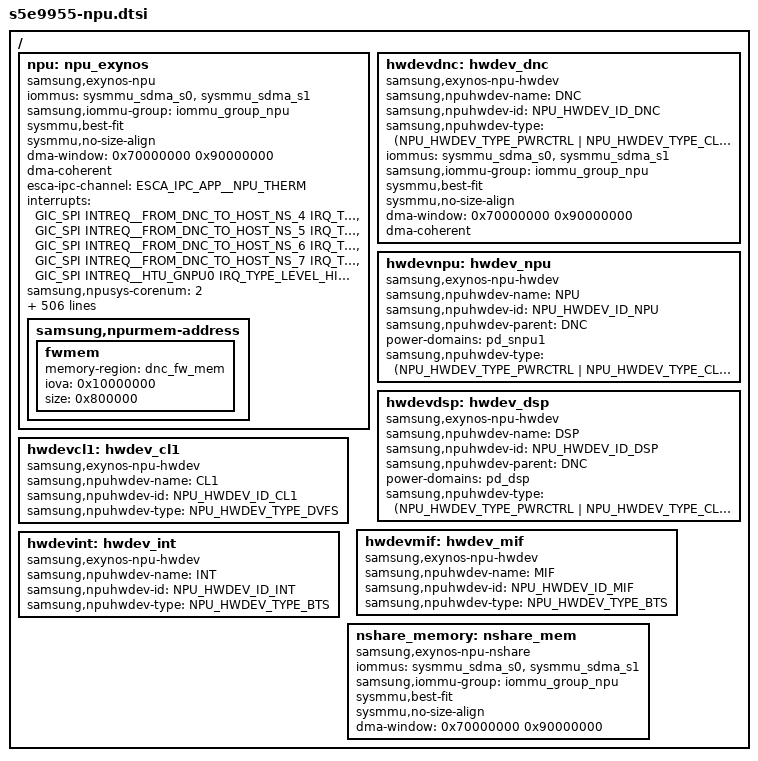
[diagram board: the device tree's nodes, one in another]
/*
 * SAMSUNG EXYNOS9955 NPU device tree source
 *
 * Copyright (c) 2024 Samsung Electronics Co., Ltd.
 *		http://www.samsung.com
 *
 * SAMSUNG EXYNOS9955 NPU device nodes are listed in this file.
 * EXYNOS based board files can include this file and provide
 * values for board specfic bindings.
 *
 * This program is free software; you can redistribute it and/or modify
 * it under the terms of the GNU General Public License version 2 as
 * published by the Free Software Foundation.
 */
#include <dt-bindings/clock/s5e9955.h>
#include <dt-bindings/soc/samsung/s5e9955-npu.h>
#include <dt-bindings/soc/samsung/s5e9955-esca-ipc.h>

/ {
	npu: npu_exynos {
		compatible = "samsung,exynos-npu";
		iommus = <&sysmmu_sdma_s0>, <&sysmmu_sdma_s1>;
		samsung,iommu-group = <&iommu_group_npu>;
		sysmmu,best-fit;
		sysmmu,no-size-align;
		#dma-address-cells = <1>;
		#dma-size-cells = <1>;
		dma-window = <0x70000000 0x90000000>;
		dma-coherent;
		esca-ipc-channel = <ESCA_IPC_APP__NPU_THERM>;

		interrupts =
			<GIC_SPI INTREQ__FROM_DNC_TO_HOST_NS_4 IRQ_TYPE_LEVEL_HIGH>,
			<GIC_SPI INTREQ__FROM_DNC_TO_HOST_NS_5 IRQ_TYPE_LEVEL_HIGH>,
			<GIC_SPI INTREQ__FROM_DNC_TO_HOST_NS_6 IRQ_TYPE_LEVEL_HIGH>,
			<GIC_SPI INTREQ__FROM_DNC_TO_HOST_NS_7 IRQ_TYPE_LEVEL_HIGH>,
			<GIC_SPI INTREQ__HTU_GNPU0 IRQ_TYPE_LEVEL_HIGH>;

		samsung,npusys-corenum = <2>;
		/* refer to npu-system.h for memory names
		 * you can add init settings for each memory area
		 */
		samsung,npumem-address = /* 0 start      size */
			<0 0x20000000 0x100000>,
			<0 0x20100000 0x100000>,
			<0 0x20200000 0x100000>,
			<0 0x20300000 0x100000>,
			<0 0x20400000 0x100000>,
			<0 0x20500000 0x100000>,
			<0 0x20600000 0x100000>,

			<0 0x21200000 0x900000>,
			<0 0x21200000 0x100000>,
			<0 0x21300000 0x200000>,
			<0 0x21500000 0x100000>,
			<0 0x21600000 0x100000>,
			<0 0x21700000 0x100000>,
			<0 0x21800000 0x100000>,
			<0 0x21900000 0x100000>,
			<0 0x21A00000 0x100000>,
			<0 0x220c0000 0x10000>,

			<0 0x400D000 0x1000>,
			<0 0x9406000 0x1000>,
			<0 0x9403000 0x1000>,
			<0 0x9404000 0x1000>,
			<0 0x13890000 0x10000>,

			<0 0x2DCA0000 0x60000>,

			<0 0x20020000 0x1000>,
			<0 0x2002084C 0x100>,
			<0 0x20022000 0x4000>,
			<0 0x20020838 0x100>,
			<0 0x216D0000 0x1000>,
			<0 0x217D0000 0x1000>,
			<0 0x218D0000 0x1000>,
			<0 0x219D0000 0x1000>,
			<0 0x13CD0000 0x10000>,

			<0 0x11100000 0x200000>,
			<2 0x11300000 0x1800000>,
			<0 0x13300000 0x800000>,
			<0 0x14000000 0x1000000>,
			<0 0x10D00000 0x100000>,
			<0 0x10E00000 0x200000>,
			<0 0x11000000 0x1000>,
			<0 0x11001000 0x7000>,
			<0 0x11008000 0xF8000>,
			<0 0x30000000 0x40000000>,
			<0 0x0 0x3000>;
		samsung,npumem-names =
				"sfrdnc",	"SFR",
				"sfrsdma",	"SFR",
				"sfrgnpu0",	"SFR",
				"sfrgnpu1",	"SFR",
				"sfrdsp0",	"SFR",
				"sfrsnpu0",	"SFR",
				"sfrsnpu1",	"SFR",

				"sfrblkall",	"SFR",
				"sfrblkdnc",	"SFR",
				"sfrblksdma",	"SFR",
				"sfrblkdsp0",	"SFR",
				"sfrblkgnpu0",	"SFR",
				"sfrblkgnpu1",	"SFR",
				"sfrblksnpu0",	"SFR",
				"sfrblksnpu1",	"SFR",
				"sfrblknpumem",	"SFR",
				"gpuc2a",	"SFR",

				"sfrcoresight",	"SFR",
				"sfrcssys_npu",	"SFR",
				"sfrstm",	"SFR",
				"sfrstm1",	"SFR",
				"sfrmctg",	"SFR",

				"pmu_sub",	"SFR",

				"sfrmboxmmap",	"SFR",
				"sfrmbox0",	"SFR",
				"sfrmbox1",	"SFR",
				"sfrmbox2",	"SFR",
				"htugnpu0",	"SFR",
				"htugnpu1",	"SFR",
				"htusnpu0",	"SFR",
				"htusnpu1",	"SFR",
				"mboxapm1dnc",	"SFR",

				"fwmbox",	"fwmbox",
				"llc",		"llc",
				"fwunittest",	"fwunittest",
				"ivp_pm",	"dsp_ivp_pm.bin",
				"dl_out",	"dl_out",
				"dsp_mem",	"dsp_mem",
				"dhcp",		"dhcp",
				"ivp_dm",	"dsp_ivp_dm.bin",
				"fwlog",	"fwlog",
				"CHUNK_IMB",	"IMB",
				"CMDQ_TABLE",	"";

		/* examples of memory area init
		 *	offset,	val,	mask,
		 * samsung,npumem-baaw =
		 *	<0x00, 0x017B00, 0xFFFFFF>,
		 *	<0x00, 0x017B40, 0xFFFFFF>,
		 *	...;
		 */

		/* examples of reg cmd
		 *	sfr : name of memory area
		 *	data :
		 *	<rw	offset	val	mask	mdelay>,
		 */

		samsung,npucmd-npupgon-sfr =
			"sfrblksdma",
			"sfrblknpumem",
			"sfrblkgnpu0",
			"sfrblkgnpu1",
			"sfrblksnpu0",
			"sfrblksnpu1";
		samsung,npucmd-npupgon-data =
			<1	0x30000	0x1	0x00000001	0>,
			<1	0x40000	0x1	0x00000001	0>,
			<1	0x40000	0x1	0x00000001	0>,
			<1	0x40000	0x1	0x00000001	0>,
			<1	0x40000	0x1	0x00000001	0>,
			<1	0x40000	0x1	0x00000001	0>;

		samsung,npucmd-dsppgon-sfr =
			"sfrblksdma",
			"sfrblkdsp0";
		samsung,npucmd-dsppgon-data =
			<1	0x30000	0x1	0x00000001	0>,
			<1	0x30000	0x1	0x00000001	0>;

		samsung,npucmd-npupgoff-sfr =
			"sfrblksdma",
			"sfrblknpumem",
			"sfrblkgnpu0",
			"sfrblkgnpu1",
			"sfrblksnpu0",
			"sfrblksnpu1";
		samsung,npucmd-npupgoff-data =
			<1	0x30000	0x0	0x00000001	0>,
			<1	0x40000	0x0	0x00000001	0>,
			<1	0x40000	0x0	0x00000001	0>,
			<1	0x40000	0x0	0x00000001	0>,
			<1	0x40000	0x0	0x00000001	0>,
			<1	0x40000	0x0	0x00000001	0>;

		samsung,npucmd-dsppgoff-sfr =
			"sfrblksdma",
			"sfrblkdsp0";
		samsung,npucmd-dsppgoff-data =
			<1	0x30000	0x0	0x00000001	0>,
			<1	0x30000	0x0	0x00000001	0>;

		samsung,npucmd-cpuon-sfr =
			/* DNC boot up */
			"sfrdnc",
			"sfrdnc",
			"sfrdnc",
			"sfrdnc",
			"sfrdnc",
			"sfrdnc",
			"sfrdnc";
		/*	cmd	offset	value	mask		delay */
		samsung,npucmd-cpuon-data =
		/* to power on, DNC_CPU_ALIVE_CTRL.CPU_ALIVE_CTRL should be 0 */
			<3	0xE0054	0x00000000	0xFFFFFFFF	0>,
			<1	0xE011C	0x00000000	0xFFFFFFFF	0>,
			<1	0xE0000	0x00000001	0xFFFFFFFF	0>,
			<3	0xE0004	0x00000001	0xFFFFFFFF	0>,
			<1	0xE0008	0x10000000	0xFFFFFFFF	0>,
			<3	0xE000C	0x10000000	0xFFFFFFFF	0>,
			<3	0xE0040	0x00000003	0xFFFFFFFF	0>;

		samsung,npucmd-cpuon64-sfr =
			/* DNC boot up */
			"sfrblkdnc",
			"sfrdnc",
			"sfrdnc",
			"sfrdnc",
			"sfrdnc",
			"sfrdnc",
			"sfrdnc",
			"sfrdnc";
		/*	cmd	offset	value	mask		delay */
		samsung,npucmd-cpuon64-data =
		/* to power on, DNC_CPU_ALIVE_CTRL.CPU_ALIVE_CTRL should be 0 */
			<1	0x600	0x00000010	0x00000010	0>,
			<3	0xE0054	0x00000001	0xFFFFFFFF	0>,
			<1	0xE011C	0x00000000	0xFFFFFFFF	0>,
			<1	0xE0000	0x00000001	0xFFFFFFFF	0>,
			<3	0xE0004	0x00000001	0xFFFFFFFF	0>,
			<1	0xE0008	0x10000000	0xFFFFFFFF	0>,
			<3	0xE000C	0x10000000	0xFFFFFFFF	0>,
			<3	0xE0040	0x00000003	0xFFFFFFFF	0>;

		samsung,npucmd-llcaid-sfr =
			"sfrblksdma",
			"sfrblksdma",
			"sfrblksdma",
			"sfrblksdma",
			"sfrblksdma",
			"sfrblksdma",
			"sfrblksdma",
			"sfrblksdma",
			"sfrblksdma",
			"sfrblksdma",
			"sfrblksdma",
			"sfrblksdma",
			"sfrblksdma",
			"sfrblksdma",
			"sfrblksdma",
			"sfrblksdma",
			"sfrblksdma",
			"sfrblksdma",
			"sfrblksdma",
			"sfrblksdma";
		/*	cmd	offset	value	mask		delay */
		samsung,npucmd-llcaid-data =
		/* llcaid stream */
			<1	0xD0420	0x101 0xFFFFFFFF 0>,
			<1	0xD0424	0xC000003 0xFFFFFFFF 0>,
			<1	0xD0428	0xC000003 0xFFFFFFFF 0>,
			<1	0xE0420	0x101 0xFFFFFFFF 0>,
			<1	0xE0424	0xC000003 0xFFFFFFFF 0>,
			<1	0xE0428	0xC000003 0xFFFFFFFF 0>,
			<1	0xF0420	0x101 0xFFFFFFFF 0>,
			<1	0xF0424	0xC000003 0xFFFFFFFF 0>,
			<1	0xF0428	0xC000003 0xFFFFFFFF 0>,
			<1	0x100420 0x101 0xFFFFFFFF 0>,
			<1	0x100424 0xC000003 0xFFFFFFFF 0>,
			<1	0x100428 0xC000003 0xFFFFFFFF 0>,
		/* llcaid master */
			<1	0xD0404	0xC000000 0xFFFFFFFF 0>,
			<1	0xD0408	0xC000000 0xFFFFFFFF 0>,
			<1	0xE0404	0xC000000 0xFFFFFFFF 0>,
			<1	0xE0408	0xC000000 0xFFFFFFFF 0>,
			<1	0xF0404	0xC000000 0xFFFFFFFF 0>,
			<1	0xF0408	0xC000000 0xFFFFFFFF 0>,
			<1	0x100404 0xC000000 0xFFFFFFFF 0>,
			<1	0x100408 0xC000000 0xFFFFFFFF 0>;

		samsung,npucmd-cpuoff-sfr =
			"sfrblkdnc",
			"sfrdnc";
		samsung,npucmd-cpuoff-data =
		/* to power off NPU cores, HWACG should be enable */
			<1	0x600	0x00		0x00000010	0>,
			<3	0xE0040	0x00000000	0xFFFFFFFF	0>;

		samsung,npucmd-cpupc-sfr =
			"sfrdnc",
			"sfrdnc";
		samsung,npucmd-cpupc-data =
			<0	0xE00CC	0x00	0xFFFFFFFF	0>,
			<0	0xE00D0	0x00	0xFFFFFFFF	0>;

		samsung,npucmd-gnpucmdqpc-sfr =
			"sfrgnpu0",
			"sfrgnpu0",
			"sfrgnpu1",
			"sfrgnpu1";
		samsung,npucmd-gnpucmdqpc-data =
			<0	0x2300	0x00	0xFFFFFFFF	0>,
			<0	0x4300	0x00	0xFFFFFFFF	0>,
			<0	0x2300	0x00	0xFFFFFFFF	0>,
			<0	0x4300	0x00	0xFFFFFFFF	0>;

		samsung,npucmd-dspcmdqpc-sfr =
			"sfrdsp0",
			"sfrdsp0";
		samsung,npucmd-dspcmdqpc-data =
			<0	0x12300	0x00	0xFFFFFFFF	0>,
			<0	0x14300	0x00	0xFFFFFFFF	0>;

		samsung,npucmd-afmgnpu0en-sfr =
			"htugnpu0",
			"htugnpu0",
			"htugnpu0",
			"htugnpu0",
			"htugnpu0",
			"htugnpu0",
			"htugnpu0",
			"htugnpu0";
		samsung,npucmd-afmgnpu0en-data =
			<1	0x200	0x00000020	0x00000020	0>,
			<1	0x06C	0x08A00008	0x08E000FC	0>,
			<1	0x080	0x02000001	0xFFF0FFF3	0>,
			<1	0x020	0x00003000	0x00003800	0>,
			<1	0x048	0x3FF0003F	0x3FF000FF	0>,
			<1	0x200	0x80000000	0x80000000	0>,
			<1	0x118	0x80000000	0xFFFFFFFF	0>,
			<1	0x000	0x00000001	0x00000001	0>;

		samsung,npucmd-afmgnpu0dis-sfr =
			"htugnpu0",
			"htugnpu0",
			"htugnpu0",
			"htugnpu0",
			"htugnpu0",
			"htugnpu0",
			"htugnpu0",
			"htugnpu0";
		samsung,npucmd-afmgnpu0dis-data =
			<1	0x200	0x00	0x00000020	0>,
			<1	0x06C	0x00	0x08E000FC	0>,
			<1	0x080	0x00	0xFFF0FFF3	0>,
			<1	0x020	0x00	0x00003800	0>,
			<1	0x048	0x00	0x3FF000FF	0>,
			<1	0x200	0x00	0x80000000	0>,
			<1	0x118	0x00	0xFFFFFFFF	0>,
			<1	0x000	0x00	0x00000001	0>;

		samsung,npucmd-afmgnpu1en-sfr =
			"htugnpu1",
			"htugnpu1",
			"htugnpu1",
			"htugnpu1",
			"htugnpu1",
			"htugnpu1",
			"htugnpu1",
			"htugnpu1";
		samsung,npucmd-afmgnpu1en-data =
			<1	0x200	0x00000020	0x00000020	0>,
			<1	0x06C	0x08A00008	0x08E000FC	0>,
			<1	0x080	0x02000001	0xFFF0FFF3	0>,
			<1	0x020	0x00003000	0x00003800	0>,
			<1	0x048	0x3FF0003F	0x3FF000FF	0>,
			<1	0x200	0x80000000	0x80000000	0>,
			<1	0x118	0x80000000	0xFFFFFFFF	0>,
			<1	0x000	0x00000001	0x00000001	0>;

		samsung,npucmd-afmgnpu1dis-sfr =
			"htugnpu1",
			"htugnpu1",
			"htugnpu1",
			"htugnpu1",
			"htugnpu1",
			"htugnpu1",
			"htugnpu1",
			"htugnpu1";
		samsung,npucmd-afmgnpu1dis-data =
			<1	0x200	0x00	0x00000020	0>,
			<1	0x06C	0x00	0x08E000FC	0>,
			<1	0x080	0x00	0xFFF0FFF3	0>,
			<1	0x020	0x00	0x00003800	0>,
			<1	0x048	0x00	0x3FF000FF	0>,
			<1	0x200	0x00	0x80000000	0>,
			<1	0x118	0x00	0xFFFFFFFF	0>,
			<1	0x000	0x00	0x00000001	0>;

		samsung,npucmd-afmsnpu0en-sfr =
			"htusnpu0",
			"htusnpu0",
			"htusnpu0",
			"htusnpu0",
			"htusnpu0",
			"htusnpu0",
			"htusnpu0",
			"htusnpu0";
		samsung,npucmd-afmsnpu0en-data =
			<1	0x200	0x00000020	0x00000020	0>,
			<1	0x06C	0x08A00008	0x08E000FC	0>,
			<1	0x080	0x02000001	0xFFF0FFF3	0>,
			<1	0x020	0x00003000	0x00003800	0>,
			<1	0x048	0x3FF0003F	0x3FF000FF	0>,
			<1	0x200	0x80000000	0x80000000	0>,
			<1	0x118	0x80000000	0xFFFFFFFF	0>,
			<1	0x000	0x00000001	0x00000001	0>;

		samsung,npucmd-afmsnpu0dis-sfr =
			"htusnpu0",
			"htusnpu0",
			"htusnpu0",
			"htusnpu0",
			"htusnpu0",
			"htusnpu0",
			"htusnpu0",
			"htusnpu0";
		samsung,npucmd-afmsnpu0dis-data =
			<1	0x200	0x00	0x00000020	0>,
			<1	0x06C	0x00	0x08E000FC	0>,
			<1	0x080	0x00	0xFFF0FFF3	0>,
			<1	0x020	0x00	0x00003800	0>,
			<1	0x048	0x00	0x3FF000FF	0>,
			<1	0x200	0x00	0x80000000	0>,
			<1	0x118	0x00	0xFFFFFFFF	0>,
			<1	0x000	0x00	0x00000001	0>;

		samsung,npucmd-afmsnpu1en-sfr =
			"htusnpu1",
			"htusnpu1",
			"htusnpu1",
			"htusnpu1",
			"htusnpu1",
			"htusnpu1",
			"htusnpu1",
			"htusnpu1";
		samsung,npucmd-afmsnpu1en-data =
			<1	0x200	0x00000020	0x00000020	0>,
			<1	0x06C	0x08A00008	0x08E000FC	0>,
			<1	0x080	0x02000001	0xFFF0FFF3	0>,
			<1	0x020	0x00003000	0x00003800	0>,
			<1	0x048	0x3FF0003F	0x3FF000FF	0>,
			<1	0x200	0x80000000	0x80000000	0>,
			<1	0x118	0x80000000	0xFFFFFFFF	0>,
			<1	0x000	0x00000001	0x00000001	0>;

		samsung,npucmd-afmsnpu1dis-sfr =
			"htusnpu1",
			"htusnpu1",
			"htusnpu1",
			"htusnpu1",
			"htusnpu1",
			"htusnpu1",
			"htusnpu1",
			"htusnpu1";
		samsung,npucmd-afmsnpu1dis-data =
			<1	0x200	0x00	0x00000020	0>,
			<1	0x06C	0x00	0x08E000FC	0>,
			<1	0x080	0x00	0xFFF0FFF3	0>,
			<1	0x020	0x00	0x00003800	0>,
			<1	0x048	0x00	0x3FF000FF	0>,
			<1	0x200	0x00	0x80000000	0>,
			<1	0x118	0x00	0xFFFFFFFF	0>,
			<1	0x000	0x00	0x00000001	0>;

		samsung,npucmd-chkgnpu0itr-sfr =
			"htugnpu0";
		samsung,npucmd-chkgnpu0itr-data =
			<0	0x06C	0x08000000	0x08000000	0>;

		samsung,npucmd-clrgnpu0itr-sfr =
			"htugnpu0";
		samsung,npucmd-clrgnpu0itr-data =
			<1	0x06C	0x08000000	0x08000000	0>;

		samsung,npucmd-engnpu0itr-sfr =
			"htugnpu0";
		samsung,npucmd-engnpu0itr-data =
			<1	0x080	0x00000003	0x00000003	0>;

		samsung,npucmd-disgnpu0itr-sfr =
			"htugnpu0";
		samsung,npucmd-disgnpu0itr-data =
			<1	0x080	0x00	0x00000003	0>;

		samsung,npucmd-clrgnpu0tdc-sfr =
			"htugnpu0";
		samsung,npucmd-clrgnpu0tdc-data =
			<1	0x080	0x00	0x0000FFF0	0>;

		samsung,npucmd-chkgnpu0tdc-sfr =
			"htugnpu0";
		samsung,npucmd-chkgnpu0tdc-data =
			<0	0x080	0x00	0x0000FFF0	0>;

		samsung,npucmd-clrdncdiv-sfr =
			"sfrblkdnc",
			"sfrblksdma";
		samsung,npucmd-clrdncdiv-data =
			<1	0x830	0x00	0x00000010	0>,
			<1	0x830	0x00	0x00000010	0>;

		samsung,npucmd-clrgnpu0div-sfr =
			"sfrblkgnpu0";
		samsung,npucmd-clrgnpu0div-data =
			<1	0x830	0x00	0x00000010	0>;

		samsung,npucmd-clrgnpu1div-sfr =
			"sfrblkgnpu1";
		samsung,npucmd-clrgnpu1div-data =
			<1	0x830	0x00	0x00000010	0>;

		samsung,npucmd-clrdspdiv-sfr =
			"sfrblkdsp0";
		samsung,npucmd-clrdspdiv-data =
			<1	0x830	0x00	0x00000010	0>;

		samsung,npucmd-enablestm-sfr =
			"sfrdnc",
			"sfrsdma",
			"sfrgnpu0",
			"sfrgnpu1",
			"sfrsnpu0",
			"sfrsnpu0",
			"sfrsnpu0",
			"sfrsnpu1",
			"sfrsnpu1",
			"sfrsnpu1",
			"sfrdsp0";
		/*	cmd	offset	value	mask		delay */
		samsung,npucmd-enablestm-data =
			<1	0x20014	0x1	0x00000001	0>,
			<1	0xF800	0x80000000	0x80000000	0>,
			<1	0x10004	0x1	0x00000001	0>,
			<1	0x10004	0x1	0x00000001	0>,
			<1	0x10004	0x1	0x00000001	0>,
			<1	0xB0200	0x1	0x00000001	0>,
			<1	0xF0200	0x1	0x00000001	0>,
			<1	0x10004	0x1	0x00000001	0>,
			<1	0xB0200	0x1	0x00000001	0>,
			<1	0xF0200	0x1	0x00000001	0>,
			<1	0x01E8	0x1	0x00000001	0>;

		samsung,npucmd-disablestm-sfr =
			"sfrdsp0",
			"sfrsnpu0",
			"sfrsnpu0",
			"sfrsnpu0",
			"sfrsnpu1",
			"sfrsnpu1",
			"sfrsnpu1",
			"sfrgnpu0",
			"sfrgnpu1",
			"sfrsdma",
			"sfrdnc";
		/*	cmd	offset	value	mask		delay */
		samsung,npucmd-disablestm-data =
			<1	0x01E8	0x0	0x00000001	0>,
			<1	0x10004	0x0	0x00000001	0>,
			<1	0xB0200	0x0	0x00000001	0>,
			<1	0xF0200	0x0	0x00000001	0>,
			<1	0x10004	0x0	0x00000001	0>,
			<1	0xB0200	0x0	0x00000001	0>,
			<1	0xF0200	0x0	0x00000001	0>,
			<1	0x10004	0x0	0x00000001	0>,
			<1	0x10004	0x0	0x00000001	0>,
			<1	0xF800	0x0	0x80000000	0>,
			<1	0x20014	0x0	0x00000001	0>;

		samsung,npucmd-enstmdnc-sfr =
		/* DNC enable stm */
			"sfrdnc",
			"sfrsdma";
		/*	cmd	offset	value	mask		delay */
		samsung,npucmd-enstmdnc-data =
		/* DNC enable stm */
			<1	0x20014	0x1	0x00000001	0>,
			<1	0xF800	0x80000000	0x80000000	0>;

		samsung,npucmd-disstmdnc-sfr =
		/* DNC disable stm */
			"sfrsdma",
			"sfrdnc";
		/*	cmd	offset	value	mask		delay */
		samsung,npucmd-disstmdnc-data =
		/* DNC disable stm */
			<1	0xF800	0x0	0x80000000	0>,
			<1	0x20014	0x0	0x00000001	0>;

		samsung,npucmd-enstmdsp-sfr =
		/* DSP enable stm */
			"sfrdsp0";
		/*	cmd	offset	value	mask		delay */
		samsung,npucmd-enstmdsp-data =
		/* DSP enable stm */
			<1	0x01E8	0x1	0x00000001	0>;

		samsung,npucmd-disstmdsp-sfr =
		/* DSP disable stm */
			"sfrdsp0";
		/*	cmd	offset	value	mask		delay */
		samsung,npucmd-disstmdsp-data =
		/* DSP disable stm */
			<1	0x01E8	0x0	0x00000001	0>;

		samsung,npucmd-enstmnpu-sfr =
		/* NPU enable stm */
			"sfrsnpu0",
			"sfrsnpu0",
			"sfrsnpu0",
			"sfrsnpu1",
			"sfrsnpu1",
			"sfrsnpu1",
			"sfrgnpu0",
			"sfrgnpu1";
		/*	cmd	offset	value	mask		delay */
		samsung,npucmd-enstmnpu-data =
		/* NPU enable stm */
			<1	0x10004	0x1	0x00000001	0>,
			<1	0xB0200	0x1	0x00000001	0>,
			<1	0xF0200	0x1	0x00000001	0>,
			<1	0x10004	0x1	0x00000001	0>,
			<1	0xB0200	0x1	0x00000001	0>,
			<1	0xF0200	0x1	0x00000001	0>,
			<1	0x10004	0x1	0x00000001	0>,
			<1	0x10004	0x1	0x00000001	0>;

		samsung,npucmd-disstmnpu-sfr =
		/* NPU disble stm */
			"sfrsnpu0",
			"sfrsnpu0",
			"sfrsnpu0",
			"sfrsnpu1",
			"sfrsnpu1",
			"sfrsnpu1",
			"sfrgnpu0",
			"sfrgnpu1";
		/*	cmd	offset	value	mask		delay */
		samsung,npucmd-disstmnpu-data =
		/* NPU disble stm */
			<1	0x10004	0x0	0x00000001	0>,
			<1	0xB0200	0x0	0x00000001	0>,
			<1	0xF0200	0x0	0x00000001	0>,
			<1	0x10004	0x0	0x00000001	0>,
			<1	0xB0200	0x0	0x00000001	0>,
			<1	0xF0200	0x0	0x00000001	0>,
			<1	0x10004	0x0	0x00000001	0>,
			<1	0x10004	0x0	0x00000001	0>;

		samsung,npucmd-allow64stm-sfr =
			"sfrstm",
			"sfrstm",
			"sfrstm",
			"sfrstm",
			"sfrstm",
			"sfrstm",
			"sfrstm";
		/*	cmd	offset	value	mask		delay */
		samsung,npucmd-allow64stm-data =
			<3	0x0D64	0x0		0xFFFFFFFF	0>,
			<3	0x0D60	0x0		0x00000001	0>,
			<3	0x0D20	0xFFFFFFFF	0xFFFFFFFF	0>,
			<3	0x0D00	0xFFFFFFFF	0xFFFFFFFF	0>,
			<3	0x0D60	0x1		0x00000001	0>,
			<3	0x0D20	0xFFFFFFFF	0xFFFFFFFF	0>,
			<3	0x0D00	0xFFFFFFFF	0xFFFFFFFF	0>;

		samsung,npucmd-allow64stm1-sfr =
			"sfrstm1",
			"sfrstm1",
			"sfrstm1",
			"sfrstm1",
			"sfrstm1",
			"sfrstm1",
			"sfrstm1";
		samsung,npucmd-allow64stm1-data =
			<3	0x0D64	0x0		0xFFFFFFFF	0>,
			<3	0x0D60	0x0		0x00000001	0>,
			<3	0x0D20	0xFFFFFFFF	0xFFFFFFFF	0>,
			<3	0x0D00	0xFFFFFFFF	0xFFFFFFFF	0>,
			<3	0x0D60	0x1		0x00000001	0>,
			<3	0x0D20	0xFFFFFFFF	0xFFFFFFFF	0>,
			<3	0x0D00	0xFFFFFFFF	0xFFFFFFFF	0>;

		samsung,npucmd-allow64ns-sfr =
			"sfrstm",
			"sfrstm",
			"sfrstm",
			"sfrstm",
			"sfrstm",
			"sfrstm",
			"sfrstm";
		/*	cmd	offset	value	mask		delay */
		samsung,npucmd-allow64ns-data =
			<1	0x0D64	0x0		0xFFFFFFFF	0>,
			<1	0x0D60	0x0		0x00000001	0>,
			<1	0x0D20	0xFFFFFFFF	0xFFFFFFFF	0>,
			<1	0x0D00	0xFFFFFFFF	0xFFFFFFFF	0>,
			<1	0x0D60	0x1		0x00000001	0>,
			<1	0x0D20	0xFFFFFFFF	0xFFFFFFFF	0>,
			<1	0x0D00	0xFFFFFFFF	0xFFFFFFFF	0>;

		samsung,npucmd-allow64ns1-sfr =
			"sfrstm1",
			"sfrstm1",
			"sfrstm1",
			"sfrstm1",
			"sfrstm1",
			"sfrstm1",
			"sfrstm1";
		samsung,npucmd-allow64ns1-data =
			<1	0x0D64	0x0		0xFFFFFFFF	0>,
			<1	0x0D60	0x0		0x00000001	0>,
			<1	0x0D20	0xFFFFFFFF	0xFFFFFFFF	0>,
			<1	0x0D00	0xFFFFFFFF	0xFFFFFFFF	0>,
			<1	0x0D60	0x1		0x00000001	0>,
			<1	0x0D20	0xFFFFFFFF	0xFFFFFFFF	0>,
			<1	0x0D00	0xFFFFFFFF	0xFFFFFFFF	0>;


		samsung,npucmd-sdma_vc0-sfr =
			"sfrsdma",
			"sfrsdma",
			"sfrsdma",
			"sfrsdma",
			"sfrsdma",
			"sfrsdma",
			"sfrsdma",
			"sfrsdma",
			"sfrsdma",
			"sfrsdma",
			"sfrsdma",
			"sfrsdma",
			"sfrsdma",
			"sfrsdma",
			"sfrsdma",
			"sfrsdma";
		samsung,npucmd-sdma_vc0-data =
			<1	0xF900	0x00	0x0000001F	0>,
			<1	0xF904	0x01	0x0000001F	0>,
			<1	0xF908	0x02	0x0000001F	0>,
			<1	0xF90C	0x03	0x0000001F	0>,
			<1	0xF910	0x04	0x0000001F	0>,
			<1	0xF914	0x05	0x0000001F	0>,
			<1	0xF918	0x06	0x0000001F	0>,
			<1	0xF91C	0x07	0x0000001F	0>,
			<1	0xF920	0x08	0x0000001F	0>,
			<1	0xF924	0x09	0x0000001F	0>,
			<1	0xF928	0x0A	0x0000001F	0>,
			<1	0xF92C	0x0B	0x0000001F	0>,
			<1	0xF930	0x0C	0x0000001F	0>,
			<1	0xF934	0x0D	0x0000001F	0>,
			<1	0xF938	0x0E	0x0000001F	0>,
			<1	0xF93C	0x0F	0x0000001F	0>;

		samsung,npucmd-sdma_vc1-sfr =
			"sfrsdma",
			"sfrsdma",
			"sfrsdma",
			"sfrsdma",
			"sfrsdma",
			"sfrsdma",
			"sfrsdma",
			"sfrsdma",
			"sfrsdma",
			"sfrsdma",
			"sfrsdma",
			"sfrsdma",
			"sfrsdma",
			"sfrsdma",
			"sfrsdma",
			"sfrsdma";
		samsung,npucmd-sdma_vc1-data =
			<1	0xF900	0x10	0x0000001F	0>,
			<1	0xF904	0x11	0x0000001F	0>,
			<1	0xF908	0x12	0x0000001F	0>,
			<1	0xF90C	0x13	0x0000001F	0>,
			<1	0xF910	0x14	0x0000001F	0>,
			<1	0xF914	0x15	0x0000001F	0>,
			<1	0xF918	0x16	0x0000001F	0>,
			<1	0xF91C	0x17	0x0000001F	0>,
			<1	0xF920	0x18	0x0000001F	0>,
			<1	0xF924	0x19	0x0000001F	0>,
			<1	0xF928	0x1A	0x0000001F	0>,
			<1	0xF92C	0x1B	0x0000001F	0>,
			<1	0xF930	0x1C	0x0000001F	0>,
			<1	0xF934	0x1D	0x0000001F	0>,
			<1	0xF938	0x1E	0x0000001F	0>,
			<1	0xF93C	0x1F	0x0000001F	0>;

		samsung,imgloader-s2mpu-support = "true";
		samsung,npusched-tpf-others = <1500>;	/* time in device driver, us */
		samsung,npusched-afmlimit = <800000>;
		samsung,npusched-min-active-cores = <1>; /* FW needs atleast one core to be active */
		samsung,npusched-dvfs =
			/* devfreq      init    delay   up      delay   down    delay
			* hispeed_idle_delay hispeed_delay hispeed_freq lowspeed_idle_delay    : exynos-interactive
			* normal       npu     cpu                             : mode minlock freq
			*/
			<&devfreq_2     1300000	30      120     75      85      75
				30      0       100     100
				1300000	1300000	0	0	1300000	1300000>,
			<&devfreq_14     935000	30      120     75      85      30
				30      0       100     100
				935000	935000	0	0	935000	935000>,
			<&devfreq_1	0	0	0	0	0	0
				0	0	0	0
				0	0	0	0	0	0>,
			<&devfreq_0	0	0	0	0	0	0
				0	0	0	0
				0	0	0	0	0	0>,
			<&devfreq_13    1200000	30      120     75      85      75
				30      0       100     100
				1200000	1200000	0	0	1200000	1200000>
			;
		samsung,npusched-names =
			"NPU",  "exynos-interactive",
			"DNC",  "exynos-interactive",
			"INT",	"",
			"MIF",	"",
			"DSP",  "exynos-interactive";

		samsung,npudvfs-open-dvfs =
			"DNC",
			"NPU",
			"DSP",
			"DSP";
		samsung,npudvfs-open-clock =
			<0	267000>,
			<0	533000>,
			<1	1200000>,
			<0	332000>;

		samsung,npudvfs-close-dvfs =
			"DNC",
			"NPU",
			"DSP";
		samsung,npudvfs-close-clock =
			<0	0>,
			<0	0>,
			<0	0>;

		samsung,npudvfs-table-num =
			/* table_index	type_num */
			<11 4>;

		samsung,npudvfs-table =
			/* core      dnc       mif      int */
			<1200000 935000 3738000 664000>,
			<1200000 800000 3172000 533000>,
			<1066000 800000 2730000 400000>,
			<935000 664000 2288000 400000>,
			<800000 533000 2028000 350000>,
			<664000 533000 1716000 350000>,
			<664000 332000 1539000 267000>,
			<533000 267000 1352000 267000>,
			<533000 267000 1014000 200000>,
			<533000 267000 845000 200000>,
			<533000 267000 676000 133000>;

		samsung,npunode-names =
			"DNC",
			"NPU",
			"DSP";

		samsung,npunode-num =
			<9>;

		samsung,npunode-freq =
			/* dnc   npu     dsp */
			<267000 533000 332000>,
			<267000 533000 533000>,
			<533000 664000 664000>,
			<664000 800000 800000>,
			<800000 934000 935000>,
			<800000 1066000 1066000>,
			<800000 1104000 1066000>,
			<935000 1152000 1200000>,
			<935000 1200000 1200000>;

		samsung,npugovernor-num =
			/* npu mif int */
			<10 13 13>;

		samsung,npugovernor-npufreq =
			/* dnc   core */
			<160000 166000>,
			<267000 533000>,
			<533000 664000>,
			<664000 800000>,
			<800000 935000>,
			<800000 1066000>,
			<800000 1104000>,
			<935000 1152000>,
			<935000 1200000>,
			<935000 1300000>;

		samsung,npugovernor-miffreq =
			<421000>,
			<676000>,
			<845000>,
			<1014000>,
			<1352000>,
			<1539000>,
			<1716000>,
			<2028000>,
			<2288000>,
			<2730000>,
			<3172000>,
			<3738000>,
			<4206000>;

		samsung,npugovernor-intfreq =
			<134000>,
			<134000>,
			<134000>,
			<134000>,
			<134000>,
			<134000>,
			<200000>,
			<267000>,
			<332000>,
			<400000>,
			<530000>,
			<664000>,
			<800000>;

		samsung,npuprecision-npufreq-num = <7>;
		samsung,npuprecision-npufreq-levels =
			/* dnc   core */
			<267000 533000>,
			<533000 664000>,
			<664000 800000>,
			<800000 935000>,
			<800000 1066000>,
			<935000 1200000>,
			<935000 1300000>;
		samsung,npuprecision-npufreq-ctrl =
			/* mid high */
			<4 6>;

		samsung,npudtm-param =
			/* target_thermal p_gain i_gain inv_gain period limit_thermal limit_frequncy */
			<93000 300 1 300 1 85000 800000>;

		samsung,npuinter-isr-cpu-affinity = "4-6";

		samsung,npuproto-task-priority = <1>;	/* SCHED_FIFO, 1 */
		samsung,npuproto-task-cpu-affinity = "4-6";

		samsung,npuafm-threshold-enable-offset = <0x18>;
		samsung,npuafm-threshold-level-offset = <0x19>;
		samsung,npuafm-threshold-level-value = <0x00>;

		samsung,npucidle-value = <0x0>;

		status = "ok";

		vertex_name = "npu";

		configs =
			<16>,		/* NPU_MAX_BUFFER */
			<3>,		/* NPU_MAX_PLANE */
			<32>,		/* NPU_MAX_GRAPH */
			<16>,		/* NPU_MAX_FRAME */
			<10>,		/* NPU_MINOR */
			<1024>,		/* NW_Q_SIZE */
			<1024>,		/* FRAME_Q_SIZE */
			<4194304>,	/* NPU_FW_LOG_KEEP_SIZE */
			<0>,		/* NPU_MAILBOX_DEFAULT_TID */
			<20>,		/* TCNTO0_OFF */
			<4096>,		/* NPU_MAILBOX_HDR_SECTION_LEN */
			<32768>,	/* NPU_MAILBOX_SIZE */
			<0x80000>,	/* NPU_MAILBOX_BASE */
			<300>,		/* POWER_DOWN_DELAY_ON_EMERGENCY */
			<12000>,	/* STREAMOFF_DELAY_ON_EMERGENCY */
			<0>,		/* NPU_FW_BASE_ADDR */
			<0>,		/* NPU_CM7_RELEASE_HACK */
			<0x50E00000>,	/* NPU_SHARED_MEM_PAYLOAD */
			<0x17EB0000>,	/* NPU_C2AGENT_0 */
			<0x17EC0000>,	/* NPU_C2AGENT_1 */
			<0x15010000>,	/* NPU_VOTF */
			<0x10000>,	/* NPU_VOTF_SIZE */
			<0>,		/* PBHA_HINT_00 */
			<1>,		/* PBHA_HINT_01 */
			<2>,		/* PBHA_HINT_10 */
			<3>,		/* PBHA_HINT_11 */
			<0x80000000>,   /* TRANSACTIONS_PER_CORE */
			<0x02000000>,   /* CMDQ_COMPLEXITY_PER_CORE */
			<1000000>,      /* LASTQ_TIME_THRESHOLD */
			<399>,		/* ALPHA */
			<24684>,	/* BETA */
			<3000>,		/* Time for clk setting */
			<0x100000>	/* NPU LLC CHUNK  size in Byte */
			;

		samsung,npurmem-address {
			fwmem {
				memory-region = <&dnc_fw_mem>;
				iova = <0x10000000>;
				size =   <0x800000>;
			};
		};
	};

	hwdevdnc: hwdev_dnc {
		compatible = "samsung,exynos-npu-hwdev";

		samsung,npuhwdev-name = "DNC";
		samsung,npuhwdev-id = <NPU_HWDEV_ID_DNC>;

//		clocks = <&clock UMUX_CLKCMU_DNC_NOC>;
//		clock-names = "dnc_noc";

		/* iommu already has parent as <&pd_npus> */
//		power-domains = <&pd_sdma>;

		samsung,npuhwdev-type =
			<(NPU_HWDEV_TYPE_PWRCTRL | NPU_HWDEV_TYPE_CLKCTRL)>;

		iommus = <&sysmmu_sdma_s0>, <&sysmmu_sdma_s1>;
		samsung,iommu-group = <&iommu_group_npu>;
		sysmmu,best-fit;
		sysmmu,no-size-align;
		#dma-address-cells = <1>;
		#dma-size-cells = <1>;
		dma-window = <0x70000000 0x90000000>;
		dma-coherent;
		status = "ok";
	};

	hwdevnpu: hwdev_npu {
		compatible = "samsung,exynos-npu-hwdev";

		samsung,npuhwdev-name = "NPU";
		samsung,npuhwdev-id = <NPU_HWDEV_ID_NPU>;
		samsung,npuhwdev-parent = "DNC";
/*
		clocks =
			<&clock UMUX_CLKCMU_NPU0_BUS_USER>;
		clock-names =
			"npu00_bus";
*/
		power-domains = <&pd_snpu1>;

		samsung,npuhwdev-type =
			<(NPU_HWDEV_TYPE_PWRCTRL | NPU_HWDEV_TYPE_CLKCTRL | NPU_HWDEV_TYPE_DVFS)>;

		status = "ok";
	};

	hwdevdsp: hwdev_dsp {
		compatible = "samsung,exynos-npu-hwdev";

		samsung,npuhwdev-name = "DSP";
		samsung,npuhwdev-id = <NPU_HWDEV_ID_DSP>;
		samsung,npuhwdev-parent = "DNC";
/*
		clocks =
			<&clock UMUX_CLKCMU_VPD_BUS_USER>,
			<&clock GATE_IP_VPD_QCH>,
			<&clock DOUT_DIV_CLK_VPD_BUSP>;
		clock-names =
			"umux_clkcmu_vpd_bus_user",
			"gate_ip_vpd_qch",
			"dout_div_clk_vpd_busp";
*/
		power-domains = <&pd_dsp>;

		samsung,npuhwdev-type =
			<(NPU_HWDEV_TYPE_PWRCTRL | NPU_HWDEV_TYPE_CLKCTRL | NPU_HWDEV_TYPE_DVFS)>;

		status = "ok";
	};

	hwdevcl1: hwdev_cl1 {
		compatible = "samsung,exynos-npu-hwdev";

		samsung,npuhwdev-name = "CL1";
		samsung,npuhwdev-id = <NPU_HWDEV_ID_CL1>;

		samsung,npuhwdev-type =
			<NPU_HWDEV_TYPE_DVFS>;

		status = "ok";
	};

	hwdevmif: hwdev_mif {
		compatible = "samsung,exynos-npu-hwdev";

		samsung,npuhwdev-name = "MIF";
		samsung,npuhwdev-id = <NPU_HWDEV_ID_MIF>;

		samsung,npuhwdev-type =
			<NPU_HWDEV_TYPE_BTS>;

		status = "ok";
	};

	hwdevint: hwdev_int {
		compatible = "samsung,exynos-npu-hwdev";

		samsung,npuhwdev-name = "INT";
		samsung,npuhwdev-id = <NPU_HWDEV_ID_INT>;

		samsung,npuhwdev-type =
			<NPU_HWDEV_TYPE_BTS>;

		status = "ok";
	};

	nshare_memory: nshare_mem {
		compatible = "samsung,exynos-npu-nshare";

		iommus = <&sysmmu_sdma_s0>, <&sysmmu_sdma_s1>;
		samsung,iommu-group = <&iommu_group_npu>;
		sysmmu,best-fit;
		sysmmu,no-size-align;
		#dma-address-cells = <1>;
		#dma-size-cells = <1>;
		dma-window = <0x70000000 0x90000000>;
		status = "ok";
	};
};

